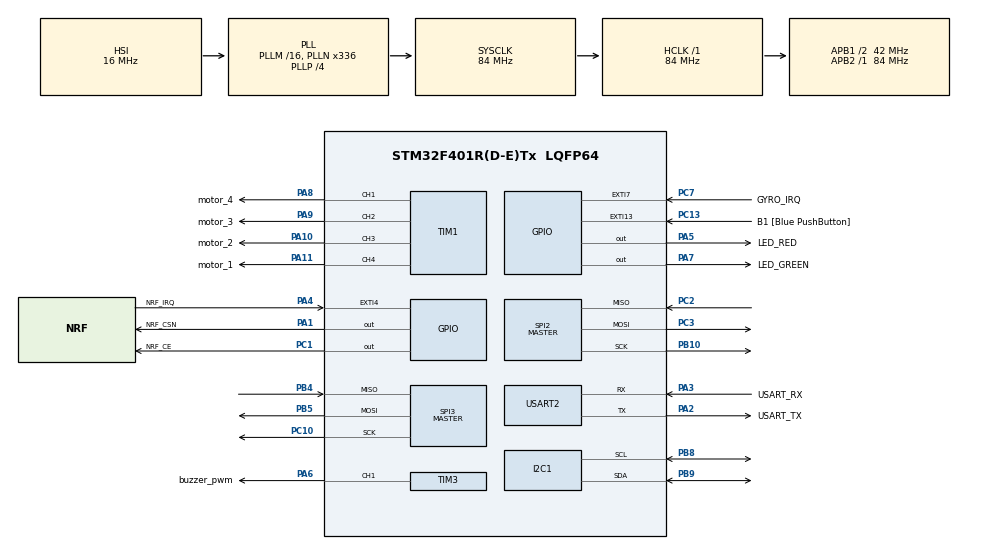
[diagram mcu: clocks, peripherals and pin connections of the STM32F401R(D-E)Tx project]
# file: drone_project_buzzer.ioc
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Mcu.Family=STM32F4
Mcu.Name=STM32F401R(D-E)Tx
Mcu.Package=LQFP64
NVIC.PriorityGroup=NVIC_PRIORITYGROUP_0
PA1.GPIO_Label=NRF_CSN
PA1.Signal=GPIO_Output
PA10.GPIO_Label=motor_2
PA10.Signal=S_TIM1_CH3
PA11.GPIO_Label=motor_1
PA11.Signal=S_TIM1_CH4
PA13.GPIO_Label=TMS
PA13.Signal=SYS_JTMS-SWDIO
PA14.GPIO_Label=TCK
PA14.Signal=SYS_JTCK-SWCLK
PA2.GPIO_Label=USART_TX
PA2.GPIO_Mode=GPIO_MODE_AF_PP
PA2.GPIO_PuPd=GPIO_NOPULL
PA2.GPIO_Speed=GPIO_SPEED_FREQ_LOW
PA2.Mode=Asynchronous
PA2.Signal=USART2_TX
PA3.GPIO_Label=USART_RX
PA3.GPIO_Mode=GPIO_MODE_AF_PP
PA3.GPIO_PuPd=GPIO_NOPULL
PA3.GPIO_Speed=GPIO_SPEED_FREQ_LOW
PA3.Mode=Asynchronous
PA3.Signal=USART2_RX
PA4.GPIO_Label=NRF_IRQ
PA4.Signal=GPXTI4
PA5.GPIO_Label=LED_RED
PA5.GPIO_Mode=GPIO_MODE_OUTPUT_PP
PA5.GPIO_PuPd=GPIO_NOPULL
PA5.GPIO_Speed=GPIO_SPEED_FREQ_LOW
PA5.Signal=GPIO_Output
PA6.GPIO_Label=buzzer_pwm
PA6.Signal=S_TIM3_CH1
PA7.GPIO_Label=LED_GREEN
PA7.Signal=GPIO_Output
PA8.GPIO_Label=motor_4
PA8.Signal=S_TIM1_CH1
PA9.GPIO_Label=motor_3
PA9.Signal=S_TIM1_CH2
PB10.Mode=Full_Duplex_Master
PB10.Signal=SPI2_SCK
PB3.GPIO_Label=SWO
PB3.Signal=SYS_JTDO-SWO
PB4.Mode=Full_Duplex_Master
PB4.Signal=SPI3_MISO
PB5.Mode=Full_Duplex_Master
PB5.Signal=SPI3_MOSI
PB8.Mode=I2C
PB8.Signal=I2C1_SCL
PB9.Mode=I2C
PB9.Signal=I2C1_SDA
PC1.GPIO_Label=NRF_CE
PC1.Signal=GPIO_Output
PC10.Mode=Full_Duplex_Master
PC10.Signal=SPI3_SCK
PC13-ANTI_TAMP.GPIO_Label=B1 [Blue PushButton]
PC13-ANTI_TAMP.GPIO_ModeDefaultEXTI=GPIO_MODE_IT_FALLING
PC13-ANTI_TAMP.GPIO_PuPd=GPIO_NOPULL
PC13-ANTI_TAMP.Signal=GPXTI13
PC14-OSC32_IN.Signal=RCC_OSC32_IN
PC15-OSC32_OUT.Signal=RCC_OSC32_OUT
PC2.Mode=Full_Duplex_Master
PC2.Signal=SPI2_MISO
PC3.Mode=Full_Duplex_Master
PC3.Signal=SPI2_MOSI
PC7.GPIO_Label=GYRO_IRQ
PC7.Signal=GPXTI7
PH0\ -\ OSC_IN.Signal=RCC_OSC_IN
PH1\ -\ OSC_OUT.Signal=RCC_OSC_OUT
ProjectManager.HeapSize=0x200
ProjectManager.StackSize=0x400
ProjectManager.TargetToolchain=STM32CubeIDE
RCC.AHBFreq_Value=84000000
RCC.APB1CLKDivider=RCC_HCLK_DIV2
RCC.APB1Freq_Value=42000000
RCC.APB1TimFreq_Value=84000000
RCC.APB2Freq_Value=84000000
RCC.APB2TimFreq_Value=84000000
RCC.CortexFreq_Value=84000000
RCC.HCLKFreq_Value=84000000
RCC.HSE_VALUE=8000000
RCC.HSI_VALUE=16000000
RCC.LSE_VALUE=32768
RCC.PLLN=336
RCC.PLLP=RCC_PLLP_DIV4
RCC.PLLQ=7
RCC.SYSCLKFreq_VALUE=84000000
RCC.SYSCLKSource=RCC_SYSCLKSOURCE_PLLCLK
RCC.VCOOutputFreq_Value=336000000
SH.S_TIM1_CH1.0=TIM1_CH1,PWM Generation1 CH1
SH.S_TIM1_CH2.0=TIM1_CH2,PWM Generation2 CH2
SH.S_TIM1_CH3.0=TIM1_CH3,PWM Generation3 CH3
SH.S_TIM1_CH4.0=TIM1_CH4,PWM Generation4 CH4
SH.S_TIM3_CH1.0=TIM3_CH1,PWM Generation1 CH1
SPI2.Direction=SPI_DIRECTION_2LINES
SPI2.Mode=SPI_MODE_MASTER
SPI2.VirtualType=VM_MASTER
SPI3.Direction=SPI_DIRECTION_2LINES
SPI3.Mode=SPI_MODE_MASTER
SPI3.VirtualType=VM_MASTER
TIM1.Channel-PWM\ Generation1\ CH1=TIM_CHANNEL_1
TIM1.Channel-PWM\ Generation2\ CH2=TIM_CHANNEL_2
TIM1.Channel-PWM\ Generation3\ CH3=TIM_CHANNEL_3
TIM1.Channel-PWM\ Generation4\ CH4=TIM_CHANNEL_4
TIM3.AutoReloadPreload=TIM_AUTORELOAD_PRELOAD_ENABLE
TIM3.Channel-PWM\ Generation1\ CH1=TIM_CHANNEL_1
TIM3.Period=21
TIM3.Prescaler=999
TIM3.Pulse-PWM\ Generation1\ CH1=11
USART2.VirtualMode=VM_ASYNC
VP_TIM3_VS_ClockSourceINT.Mode=Internal
board=NUCLEO-F401RE

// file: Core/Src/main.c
/* USER CODE BEGIN Header */
/**
  ******************************************************************************
  * @file           : main.c
  * @brief          : Main program body
  ******************************************************************************
  * @attention
  *
  * Copyright (c) 2024 STMicroelectronics.
  * All rights reserved.
  *
  * This software is licensed under terms that can be found in the LICENSE file
  * in the root directory of this software component.
  * If no LICENSE file comes with this software, it is provided AS-IS.
  *
  ******************************************************************************
  */
/* USER CODE END Header */
#include "main.h"
#include "i2c.h"
#include "spi.h"
#include "tim.h"
#include "usart.h"
#include "gpio.h"

void SystemClock_Config(void);

int main(void)
{

  /* MCU Configuration--------------------------------------------------------*/

  /* Reset of all peripherals, Initializes the Flash interface and the Systick. */
  HAL_Init();

  /* Configure the system clock */
  SystemClock_Config();

  /* Initialize all configured peripherals */
  MX_GPIO_Init();
  MX_SPI2_Init();
  MX_I2C1_Init();
  MX_SPI3_Init();
  MX_TIM1_Init();
  MX_TIM3_Init();
  MX_USART2_UART_Init();
  /* USER CODE BEGIN 2 */

  LL_TIM_EnableCounter(TIM3);
  LL_TIM_CC_EnableChannel(TIM3, LL_TIM_CHANNEL_CH1);
  HAL_Delay(100) ;
  LL_TIM_SetAutoReload(TIM3, 40) ;
  HAL_Delay(100) ;
  LL_TIM_SetAutoReload(TIM3, 45) ;
  HAL_Delay(100) ;
  LL_TIM_SetAutoReload(TIM3, 50) ;
  HAL_Delay(100) ;
  LL_TIM_SetAutoReload(TIM3, 21) ;
  HAL_Delay(100) ;
  LL_TIM_CC_DisableChannel(TIM3, LL_TIM_CHANNEL_CH1) ;
  /* USER CODE END 2 */

  /* Infinite loop */
  while (1)
  {

    /* USER CODE BEGIN 3 */

	  LL_GPIO_TogglePin(LED_RED_GPIO_Port, LED_RED_Pin | LED_GREEN_Pin);
	  HAL_Delay(1000) ;
  }
  /* USER CODE END 3 */
}

void SystemClock_Config(void)
{
  RCC_OscInitTypeDef RCC_OscInitStruct = {0};
  RCC_ClkInitTypeDef RCC_ClkInitStruct = {0};

  /** Configure the main internal regulator output voltage
  */
  __HAL_RCC_PWR_CLK_ENABLE();
  __HAL_PWR_VOLTAGESCALING_CONFIG(PWR_REGULATOR_VOLTAGE_SCALE2);

  /** Initializes the RCC Oscillators according to the specified parameters
  * in the RCC_OscInitTypeDef structure.
  */
  RCC_OscInitStruct.OscillatorType = RCC_OSCILLATORTYPE_HSI;
  RCC_OscInitStruct.HSIState = RCC_HSI_ON;
  RCC_OscInitStruct.HSICalibrationValue = RCC_HSICALIBRATION_DEFAULT;
  RCC_OscInitStruct.PLL.PLLState = RCC_PLL_ON;
  RCC_OscInitStruct.PLL.PLLSource = RCC_PLLSOURCE_HSI;
  RCC_OscInitStruct.PLL.PLLM = 16;
  RCC_OscInitStruct.PLL.PLLN = 336;
  RCC_OscInitStruct.PLL.PLLP = RCC_PLLP_DIV4;
  RCC_OscInitStruct.PLL.PLLQ = 7;
  if (HAL_RCC_OscConfig(&RCC_OscInitStruct) != HAL_OK)
  {
    Error_Handler();
  }

  /** Initializes the CPU, AHB and APB buses clocks
  */
  RCC_ClkInitStruct.ClockType = RCC_CLOCKTYPE_HCLK|RCC_CLOCKTYPE_SYSCLK
                              |RCC_CLOCKTYPE_PCLK1|RCC_CLOCKTYPE_PCLK2;
  RCC_ClkInitStruct.SYSCLKSource = RCC_SYSCLKSOURCE_PLLCLK;
  RCC_ClkInitStruct.AHBCLKDivider = RCC_SYSCLK_DIV1;
  RCC_ClkInitStruct.APB1CLKDivider = RCC_HCLK_DIV2;
  RCC_ClkInitStruct.APB2CLKDivider = RCC_HCLK_DIV1;

  if (HAL_RCC_ClockConfig(&RCC_ClkInitStruct, FLASH_LATENCY_2) != HAL_OK)
  {
    Error_Handler();
  }
}

void Error_Handler(void)
{
  __disable_irq();
  while (1)
  {
  }
}
